# pse84 register map
Vendor: Cypress Semiconductor; Series: PSE84; File version: 1.0
CPU: CM33 r0p1, little endian, MPU, FPU, VTOR, 3 interrupt priority bits
Registers are 32-bit, read-write, reset 0x0 unless marked. A register's access mark holds for its fields unless they carry their own. Offsets are from the block's base; [hi:lo] are bit positions; lines under a group give offsets from that group; {n}, {i} and the like mark numbered series; 'fields as' and 'values as' point back to an identical list; <NAME> marks a mode.

## SRSS (part 3 of 3) — SRSS Core Registers
Base 0x42400000
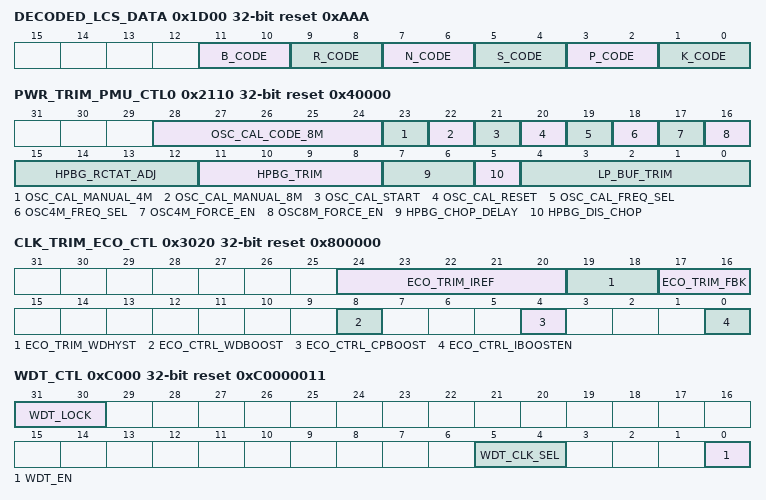
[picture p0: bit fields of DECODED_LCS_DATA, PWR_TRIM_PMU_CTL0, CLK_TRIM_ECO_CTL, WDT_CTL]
0x1D00 DECODED_LCS_DATA ro reset 0xAAA — Decoded Life Cycle Stage Data Register
  [11:10] B_CODE — Indicates status of LCS 'B' bit. 00=Unprogrammed, 11=Valid, 10/01=Invalid
  [9:8] R_CODE — Indicates status of LCS 'R' bit. 00=Unprogrammed, 11=Valid, 10/01=Invalid
  [7:6] N_CODE — Indicates status of LCS 'N' bit*. 00=Unprogrammed, 11=Valid, 10/01=Invalid. Will be '00' if R_CODE is set in RMA LCS
  [5:4] S_CODE — Indicates status of LCS 'S' bit*. 00=Unprogrammed, 11=Valid, 10/01=Invalid. Will be '11' if R_CODE is set in RMA LCS
  [3:2] P_CODE — Indicates status of LCS 'P' bit*. 00=Unprogrammed, 11=Valid, 10/01=Invalid. Will be '11' if R_CODE is set in RMA LCS
  [1:0] K_CODE — Indicates status of LCS 'K' bit. 00=Unprogrammed, 11=Valid, 10/01=Invalid
0x2110 PWR_TRIM_PMU_CTL0 reset 0x40000 — PMU Trim Register 0
  [28:24] OSC_CAL_CODE_8M — Manual trim code to apply to 8MHz oscillator. Only used if osc_cal_manual_8M=1.
  [23] OSC_CAL_MANUAL_4M — Set to use manual cal code for 3.2/4MHz oscillator 0 Use calibration result 1 Use osc_cal_code_4M<4:0>
  [22] OSC_CAL_MANUAL_8M — Set to use manual cal code for 8MHz oscillator 0 Use calibration result 1 Use osc_cal_code_8M<4:0>
  [21] OSC_CAL_START — Start oscillator calibration
  [20] OSC_CAL_RESET — Reset osc cal codes and cal_done signal
  [19] OSC_CAL_FREQ_SEL — Select oscillator to calibrate 0: 8MHz 1: 3.2M/4MHz
  [18] OSC4M_FREQ_SEL — PWM oscillator frequency select 0: 4.0MHz 1 : 3.2MHz
  [17] OSC4M_FORCE_EN — 3.2/4MHz (PWM) oscillator enable - use for Calibration 0: Auto (powerup when used) 1: Enabled (3.2/4MHz always on)
  [16] OSC8M_FORCE_EN — 8MHz oscillator enable - use for Calibration 0: Auto (powerup when used) 1: Enabled (8MHz always on)
  [15:12] HPBG_RCTAT_ADJ — High power bandgap adjust for 0TC (TTTT,50C)
  [11:8] HPBG_TRIM — High power bandgap reference voltage trim Setting VOUT @1.16V VOUT percent 0111 41mV +3.4 percent 0110 35mV +2.9 percent 0101 29mV +2.4 percent 0100 23mV +1.9 percent 0011 18mV +1.5 percent 0010 12mV +1.0 percent 0001 6mV +0.5 percent 0000 0mV 0.0 percent 1111 -5mV -0.4 percent 1110 -11mV -1.0 percent 1101 -16mV -1.4 percent 1100 -22mV -1.9 percent 1011 -27mV -2.4 percent 1010 -32mV -2.8 percent 1001 -38mV -3.4 percent 1000 -43mV -3.9 percent
  [7:6] HPBG_CHOP_DELAY — HPBG chopping delay Setting Delay 00 16us 01 32us 10 64us 11 128us
  [5] HPBG_DIS_CHOP — HPBG disable chop
  [4:0] LP_BUF_TRIM — LP buffer voltage trim, 2's compliment format Setting Vref(V) Setting Vref(V) 00000 0.600 10000 0.520 (-13.3 percent) 00001 0.605 (+0.83 percent) 10001 0.525 (-12.5 percent) 00010 0.610 (+1.67 percent) 10010 0.530 (-11.7 percent) 00011 0.615 (+2.50 percent) 10011 0.535 (-10.8 percent) 00100 0.620 (+3.33 percent) 10100 0.540 (-10.0 percent) 00101 0.625 (+4.17 percent) 10101 0.545 (-9.17 percent) 00110 0.630 (+5.00 percent) 10110 0.550 (-8.33 percent) 00111 0.635 (+5.83 percent) 10111 0.555 (-7.50 percent) 01000 0.640 (+6.67 percent) 11000 0.560 (-6.67 percent) 01001 0.645 (+7.50 percent) 11001 0.565 (-5.83 percent) 01010 0.650 (+8.33 percent) 11010 0.570 (-5.00 percent) 01011 0.655 (+9.17 percent) 11011 0.575 (-4.17 percent) 01100 0.660 (+10.0 percent) 11100 0.580 (-3.33 percent) 01101 0.665 (+10.8 percent) 11101 0.585 (-2.50 percent) 01110 0.670 (+11.7 percent) 11110 0.590 (-1.67 percent) 01111 0.675 (+12.5 percent) 11111 0.595 (-0.83 percent)
0x3020 CLK_TRIM_ECO_CTL reset 0x800000 — ECO Trim Register
  [24:20] ECO_TRIM_IREF — Current bias trim input pin
  [19:18] ECO_TRIM_WDHYST — Watchdog hysteresis trim
  [17:16] ECO_TRIM_FBK — Feedback resistance trim
  [8] ECO_CTRL_WDBOOST — Watchdog trim
  [4] ECO_CTRL_CPBOOST — Amplitude trim
  [0] ECO_CTRL_IBOOSTEN — Current boost enable input pin
0x4000 RAM_TRIM group — SRAM Trim registers
  {0x0+4j} TRIM_RAM_CTL[{j}] (j=0..9) — Trim Register for RAM Type 0
    [31:0] TRIM — Trim value for RAM Type 0
0xC000 WDT_CTL reset 0xC0000011 — Watchdog Counter Control Register (Type A)
  [31:30] WDT_LOCK — Prohibits writing to WDT_*, CLK_ILO_CONFIG, CLK_SELECT.LFCLK_SEL, and CLK_TRIM_ILO_CTL registers when not equal 0. Requires at least two different writes to unlock. A change in WDT_LOCK takes effect beginning with the next write cycle. Note that this field is 2 bits to force multiple writes only. It represents only a single write protect signal protecting all those registers at the same time. WDT will lock on any reset. This field is not retained during DEEPSLEEP or HIBERNATE mode, so the WDT will be locked after wakeup from these modes.
    0=NO_CHG (No effect); 1=CLR0 (Clears bit 0); 2=CLR1 (Clears bit 1); 3=SET01 (Sets both bits 0 and 1)
  [5:4] WDT_CLK_SEL — Select source for WDT. Not all products support all clock sources. Selecting a clock source that is not supported will result in undefined behavior. Writes to this field are ignored unless the WDT is unlock using WDT_LOCK register. It takes four cycles of the originally selected clock to switch away from it. Do not disable the original clock during this time.
    0=ILO (ILO - Internal Low-speed Oscillator, if present. With this option selected, ILO reset is suppressed in Hibernate mode.); 1=PILO (PILO - Precision ILO. If present. With this option selected, PILO reset is suppressed in Hibernate mode.); 2=RTC (RTC - Selected clk_rtc source, if present. This choice is not recommended for applications that rely upon the watchdog timer for safety or security, unless the product supports clock supervision of clk_rtc (CSV_RTC). Generation of clk_rtc is not protected by WDT_LOCK and is in a different memory region with potentially different security attributes.)
  [0] WDT_EN — Enable this watchdog timer. This field is retained during DEEPSLEEP and HIBERNATE modes.
0xC004 WDT_CNT — Watchdog Counter Count Register (Type A)
  [31:0] COUNTER — Current value of WDT Counter. The write feature of this register is for verification purpose, have no synchronization, and can only be applied when the WDT is fully off. When writing, the value is updated immediately in the WDT counter, but it will read back as the old value until this register resynchronizes just after the negedge of selected WDT clock. Writes will be ignored if they occur when the WDT is enabled.
0xC008 WDT_MATCH reset 0x1000 — Watchdog Counter Match Register (Type A)
  [31:0] MATCH — Match value for Watchdog counter. Every time WDT_COUNTER reaches MATCH an interrupt is generated. Two unserviced interrupts will lead to a system reset (i.e. at the third match).
0xC00C WDT_MATCH2 reset 0x1F — Watchdog Counter Match Register 2 (Type A)
  [4:0] IGNORE_BITS_ABOVE — The number of bits to be considered for matching starting from LSb of the register. Bit indices above this setting are NOT checked against MATCH. This value provides control over the time-to-reset of the watchdog (which happens after 3 successive matches). The four LSBs cannot be ignored for matching. Settings <3 behave like a setting of 3. If the setting is higher than the number of bits in the WDT counter, all actual bits in the counter are matched.
{0xC100+0x80*i} WDT[{i}] (i=0..3) group — Watchdog Timer (Type B)
  0x00 CTL reset 0x80000001 — WDT Control Register
    [31] ENABLE — Enable watchdog. May take up to three clk_ilo0 cycles to take effect. When ENABLE changes from 1->0, the counter is cleared. Do not enter DEEPSLEEP or HIBERNATE mode if ENABLE<>ENABLED. This can be done by waiting until ENABLE==ENABLED whenever ENABLE is changed. 0: Counter is disabled (not clocked). 1: Counter is enabled (counting up)
    [0] ENABLED ro — Indicates actual state of watchdog. May lag ENABLE by up to three clk_ilo0 cycles.
  0x04 LOWER_LIMIT — WDT Lower Limit Register
    [31:0] LOWER_LIMIT — Lower limit for watchdog. See LOWER_ACTION.
  0x08 UPPER_LIMIT reset 0x8000 — WDT Upper Limit Register
    [31:0] UPPER_LIMIT — Upper limit for watchdog. See UPPER_ACTION.
  0x0C WARN_LIMIT — WDT Warn Limit Register
    [31:0] WARN_LIMIT — Warn limit for watchdog. See WARN_ACTION.
  0x10 CONFIG reset 0x10 — WDT Configuration Register
    [31] DEBUG_RUN — Pauses/runs this counter while a debugger is connected. Other behaviors are unchanged during debugging, including service, configuration updates and enable/disable. Note it may take up to two clk_ilo0 cycles for the counter to pause and another two cycles to unpause, due to internal synchronization. If the debugger is connected for at least two clk_ilo0 cycles, the LOWER_ACTION is ignored until after the first service after the debugger is disconnected. This prevents an unintentional trigger of the LOWER_ACTION before the firmware realigns the servicing period. After the first service, LOWER_ACTION behaves as configured. If the debugger is disconnected before two clk_ilo0 cycles, the LOWER_ACTION may or may not be ignored. 0: When debugger connected, counter pauses incrementing as configured in DEBUG_TRIGGER_EN. 1: When debugger connected, counter increments normally, but reset generation is blocked.
    [30] HIB_PAUSE — Pauses/runs this counter when the system is in HIBERNATE. Note it may take up to two clk_ilo0 cycles for the counter to pause, due to internal synchronization. After wakeup, the LOWER_ACTION is ignored until after the first service. This prevents an unintentional trigger of the LOWER_ACTION before the firmware realigns the servicing period. After the first service, LOWER_ACTION behaves as configured. 0: Counter behaves normally during HIBERNATE. 1: Counter pauses during HIBERNATE.
    [29] DPSLP_PAUSE — Pauses/runs this counter when the system is in DEEPSLEEP. Note it may take up to two clk_ilo0 cycles for the counter to pause, due to internal synchronization. During DEEPSLEEP wakeup, the pause request is removed when clk_hf0 starts clocking, and then it may take up to two clk_ilo0 cycles for the counter to start. After wakeup, the LOWER_ACTION is ignored until after the first service. This prevents an unintentional trigger of the LOWER_ACTION before the firmware realigns the servicing period. After the first service, LOWER_ACTION behaves as configured. 0: Counter behaves normally during DEEPSLEEP. 1: Counter pauses during DEEPSLEEP.
    [28] DEBUG_TRIGGER_EN — Enables the trigger input for WDT to pause the counter during debug mode. To pause at a breakpoint while debugging, configure the trigger matrix to connect the related CPU halted signal to the trigger input for this WDT, and then set this bit. It takes up to two clk_ilo0 cycles for the trigger signal to be processed. Triggers that are less than two clk_ilo0 cycles may be missed. Synchronization error can accumulate each time it is halted. 0: Pauses the counter whenever a debug probe is connected. 1: Pauses the counter whenever a debug probe is connected and the trigger input is high.
    [12] AUTO_SERVICE — Automatically service when the count value reaches WARN_LIMIT. This allows creation of a periodic interrupt if this counter is not needed as a watchdog. This field is ignored when LOWER_ACTION<>NOTHING or when UPPER_ACTION<>NOTHING.
    [8] WARN_ACTION — Action taken when the count value reaches WARN_LIMIT. The minimum setting to achieve a periodic interrupt is WARN_LIMIT==1. A setting of zero will trigger once but not periodically. For WARN_LIMIT >= 2: The action is triggered on same edge when it meets this condition. For WARN_LIMIT < 2 : The action may take up to one extra clk_ilo0 cycle to trigger.
      0=NOTHING (Do nothing); 1=INT (Trigger an interrupt.)
    [4] UPPER_ACTION — Action taken if this watchdog is not serviced before UPPER_LIMIT is reached. The counter stops counting when UPPER_LIMIT is reached, regardless of UPPER_ACTION setting. UPPER_ACTION is ignored (i.e. treated as NOTHING) when a debugger is connected. For UPPER_LIMIT >= 2: The action is triggered on same edge when it meets this condition. For UPPER_LIMIT < 2: The action may take up to one extra clk_ilo0 cycle to trigger.
      0=NOTHING (Do nothing); 1=RESET (Trigger a reset.)
    [0] LOWER_ACTION — Action taken if this watchdog is serviced before LOWER_LIMIT is reached. LOWER_ACTION is ignored (i.e. treated as NOTHING) when a debugger is connected and/or when the chip is in DEEPSLEEP/HIBERNATE modes. For LOWER_LIMIT >= 1: The action is triggered on same edge when it meets this condition. For LOWER_LIMIT == 0: No action is triggered.
      0=NOTHING (Do nothing); 1=RESET (Trigger a reset.)
  0x14 CNT — WDT Count Register
    [31:0] CNT — Current value of subcounter for this WDT. This field may lag the actual count value by up to one clk_ilo0 cycle, due to internal synchronization. When this subcounter is disabled and unlocked, the count value can be written for verification and debugging purposes. Software writes are always ignored when the subcounter is enabled.
  0x40 LOCK reset 0x3 — WDT Lock register
    [1:0] WDT_LOCK — Prohibits writing control and configuration registers related to this WDT when not equal 0 (as specified in the other register descriptions). Requires at least two different writes to unlock. Note that this field is 2 bits to force multiple writes only. This register also locks the clk_ilo0 settings.
      values as WDT_CTL.WDT_LOCK
  0x44 SERVICE — WDT Service register
    [0] SERVICE — Services the watchdog. This resets the count value to zero. This may take up to three clk_ilo0 cycle to take effect. Hardware clears this bit, after necessary synchronization. To ensure a pending SERVICE write is reflected, firmware should wait until this bit reads low before attempting to write SERVICE=1. If WDT is disabled, SERVICE will not trigger a LOWER_ACTION and will not clear a preloaded count value.
  0x50 INTR — WDT Interrupt Register
    [0] WDT — WDT Interrupt Request. This bit is set as configured by WDT action and limits. Due to internal synchronization, it takes up to 8 SYSCLK cycles to update after a W1C or reading this register and during this time AHB bus is stalled.
  0x54 INTR_SET — WDT Interrupt Set Register
    [0] WDT — Set interrupt. Due to internal synchronization, it takes up to 8 SYSCLK cycles to update after a W1S or reading from this register and during this time AHB bus is stalled.
  0x58 INTR_MASK — WDT Interrupt Mask Register
    [0] WDT — Mask for watchdog timer. Clearing this bit will not forward the interrupt to the CPU.
  0x5C INTR_MASKED ro — WDT Interrupt Masked Register
    [0] WDT — Logical and of corresponding request and mask bits. Due to internal synchronization, it takes up to 8 SYSCLK cycles to read from this register. During this time AHB bus is stalled.
{0xD000+0x40*i} MCWDT_STRUCT[{i}] (i=0..1) group — Multi-Counter Watchdog Timer (Type A)
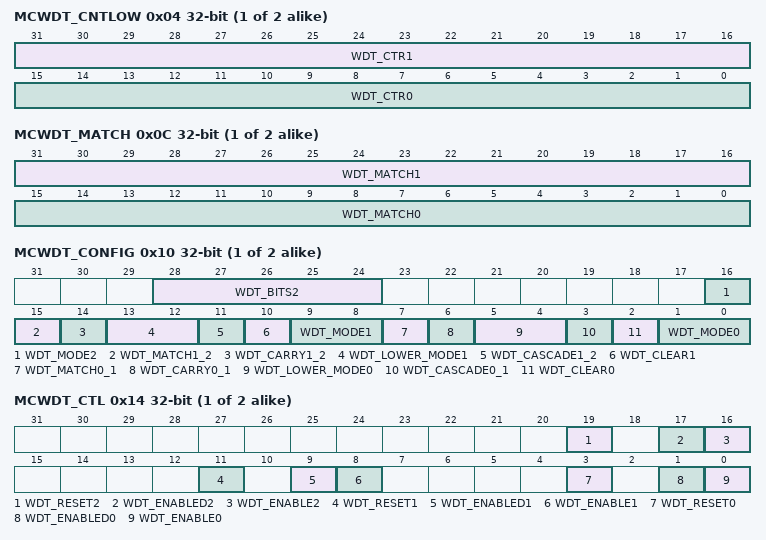
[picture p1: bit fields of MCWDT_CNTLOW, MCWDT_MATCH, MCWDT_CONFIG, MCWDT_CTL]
  0x04 MCWDT_CNTLOW — Multi-Counter Watchdog Sub-counters 0/1
    [31:16] WDT_CTR1 — Current value of sub-counter 1 for this MCWDT. Software writes are ignored when the sub-counter is enabled
    [15:0] WDT_CTR0 — Current value of sub-counter 0 for this MCWDT. Software writes are ignored when the sub-counter is enabled.
  0x08 MCWDT_CNTHIGH — Multi-Counter Watchdog Sub-counter 2
    [31:0] WDT_CTR2 — Current value of sub-counter 2 for this MCWDT. Software writes are ignored when the sub-counter is enabled
  0x0C MCWDT_MATCH — Multi-Counter Watchdog Counter Match Register
    [31:16] WDT_MATCH1 — Match value for sub-counter 1 of this MCWDT
    [15:0] WDT_MATCH0 — Match value for sub-counter 0 of this MCWDT
  0x10 MCWDT_CONFIG — Multi-Counter Watchdog Counter Configuration
    [28:24] WDT_BITS2 — Bit to observe for WDT_INT2: 0: Assert after bit0 of WDT_CTR2 toggles (one int every tick) ... 31: Assert after bit31 of WDT_CTR2 toggles (one int every 2^31 ticks)
    [16] WDT_MODE2 — Watchdog Counter 2 Mode.
      0=NOTHING (Free running counter with no interrupt requests); 1=INT (Free running counter with interrupt request that occurs one LFCLK cycle after the specified bit in CTR2 toggles (see WDT_BITS2).)
    [15] WDT_MATCH1_2 — Specifies matching behavior when WDT_CASCADE1_2==1. When WDT_CASCADE1_2==0, this bit is not used and match is based on counter 2 alone. 0: Match based on counter 2 alone. 1: Match based on counter 2 and counter 1 matching simultaneously.
    [14] WDT_CARRY1_2 — Carry out behavior that applies when WDT_CASCADE1_2==1. This bit is not used when WDT_CASCADE1_2==0. 0: carry out on counter 1 match. 1: carry out on counter 1 roll-over.
    [13:12] WDT_LOWER_MODE1 — Watchdog Counter Action on service before lower limit.
      0=NOTHING (Do nothing); 1=INT (Assert WDT_INTx); 2=RESET (Assert WDT Reset)
    [11] WDT_CASCADE1_2 — Cascade Watchdog Counters 1,2. Counter 2 increments the cycle after WDT_CTR1=WDT_MATCH1. It is allowed to cascade all three WDT counters. 0: Independent counters 1: Cascaded counters. When cascading all three counters, WDT_CLEAR1 must be 1.
    [10] WDT_CLEAR1 — Clear Watchdog Counter when WDT_CTR1==WDT_MATCH1. In other words WDT_CTR1 divides LFCLK by (WDT_MATCH1+1). 0: Free running counter 1: Clear on match. In this mode, the minimum legal setting of WDT_MATCH1 is 1.
    [9:8] WDT_MODE1 — Watchdog Counter Action on Match. Action is taken on the next increment after the values match (WDT_CTR1=WDT_MATCH1).
      0=NOTHING (Do nothing); 1=INT (Assert WDT_INTx); 2=RESET (Assert WDT Reset); 3=INT_THEN_RESET (Assert WDT_INTx, assert WDT Reset after 3rd unhandled interrupt)
    [7] WDT_MATCH0_1 — Specifies matching behavior when WDT_CASCADE0_1==1. When WDT_CASCADE0_1==0, this bit is not used and match is based on counter 1 alone. 0: Match based on counter 1 alone. 1: Match based on counter 1 and counter 0 matching simultaneously.
    [6] WDT_CARRY0_1 — Carry out behavior that applies when WDT_CASCADE0_1==1. This bit is not used when WDT_CASCADE0_1==0. 0: carry out on counter 0 match. 1: carry out on counter 0 roll-over.
    [5:4] WDT_LOWER_MODE0 — Watchdog Counter Action on service before lower limit.
      values as WDT_LOWER_MODE1
    [3] WDT_CASCADE0_1 — Cascade Watchdog Counters 0,1. Counter 1 increments the cycle after WDT_CTR0=WDT_MATCH0. 0: Independent counters 1: Cascaded counters
    [2] WDT_CLEAR0 — Clear Watchdog Counter when WDT_CTR0=WDT_MATCH0. In other words WDT_CTR0 divides LFCLK by (WDT_MATCH0+1). 0: Free running counter 1: Clear on match. In this mode, the minimum legal setting of WDT_MATCH0 is 1.
    [1:0] WDT_MODE0 — Watchdog Counter Action on Match. Action is taken on the next increment after the values match (WDT_CTR0=WDT_MATCH0).
      values as WDT_MODE1
  0x14 MCWDT_CTL — Multi-Counter Watchdog Counter Control
    [19] WDT_RESET2 — Resets counter 2 back to 0000. Hardware will reset this bit after counter was reset. This will take up to one LFCLK cycle to take effect.
    [17] WDT_ENABLED2 ro — Indicates actual state of counter. May lag WDT_ENABLE2 by up to two LFCLK cycles.
    [16] WDT_ENABLE2 — Enable subcounter 2. May take up to 2 LFCLK cycles to take effect. 0: Counter is disabled (not clocked) 1: Counter is enabled (counting up)
    [11] WDT_RESET1 — Resets counter 1 back to 0000. Hardware will reset this bit after counter was reset. This will take up to one LFCLK cycle to take effect.
    [9] WDT_ENABLED1 ro — Indicates actual state of counter. May lag WDT_ENABLE1 by up to two LFCLK cycles.
    [8] WDT_ENABLE1 — Enable subcounter 1. May take up to 2 LFCLK cycles to take effect. 0: Counter is disabled (not clocked) 1: Counter is enabled (counting up)
    [3] WDT_RESET0 — Resets counter 0 back to 0000. Hardware will reset this bit after counter was reset. This will take up to one LFCLK cycle to take effect.
    [1] WDT_ENABLED0 ro — Indicates actual state of counter. May lag WDT_ENABLE0 by up to two LFCLK cycles.
    [0] WDT_ENABLE0 — Enable subcounter 0. May take up to 2 LFCLK cycles to take effect. 0: Counter is disabled (not clocked) 1: Counter is enabled (counting up)
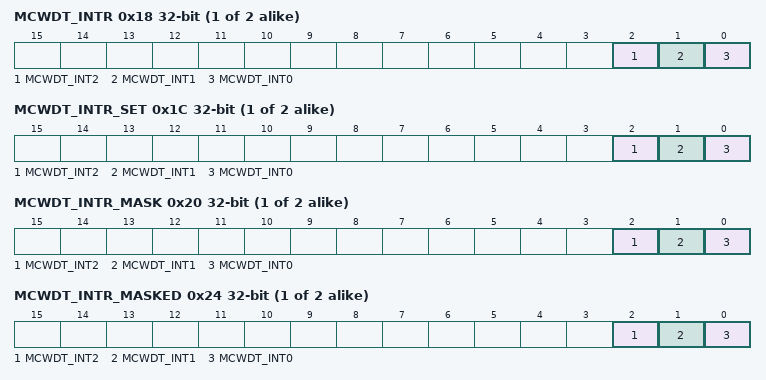
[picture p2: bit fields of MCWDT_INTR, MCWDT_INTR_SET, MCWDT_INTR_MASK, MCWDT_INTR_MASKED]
  0x18 MCWDT_INTR — Multi-Counter Watchdog Counter Interrupt Register
    [2] MCWDT_INT2 — MCWDT Interrupt Request for sub-counter 2. This bit is set by hardware as configured by this registers. This bit must be cleared by firmware. Clearing this bit also prevents Reset from happening when WDT_MODE2=3.
    [1] MCWDT_INT1 — MCWDT Interrupt Request for sub-counter 1. This bit is set by hardware as configured by this registers. This bit must be cleared by firmware. Clearing this bit also prevents Reset from happening when WDT_MODE1=3.
    [0] MCWDT_INT0 — MCWDT Interrupt Request for sub-counter 0. This bit is set by hardware as configured by this registers. This bit must be cleared by firmware. Clearing this bit also prevents Reset from happening when WDT_MODE0=3.
  0x1C MCWDT_INTR_SET — Multi-Counter Watchdog Counter Interrupt Set Register
    [2] MCWDT_INT2 — Set interrupt for MCWDT_INT2
    [1] MCWDT_INT1 — Set interrupt for MCWDT_INT1
    [0] MCWDT_INT0 — Set interrupt for MCWDT_INT0
  0x20 MCWDT_INTR_MASK — Multi-Counter Watchdog Counter Interrupt Mask Register
    [2] MCWDT_INT2 — Mask for sub-counter 2. This controls if the interrupt is forwarded to the CPU. 0: Interrupt is masked (not forwarded). 1: Interrupt is forwarded.
    [1] MCWDT_INT1 — Mask for sub-counter 1. This controls if the interrupt is forwarded to the CPU. 0: Interrupt is masked (not forwarded). 1: Interrupt is forwarded.
    [0] MCWDT_INT0 — Mask for sub-counter 0. This controls if the interrupt is forwarded to the CPU. 0: Interrupt is masked (not forwarded). 1: Interrupt is forwarded.
  0x24 MCWDT_INTR_MASKED ro — Multi-Counter Watchdog Counter Interrupt Masked Register
    [2] MCWDT_INT2 — Logical and of corresponding request and mask bits.
    [1] MCWDT_INT1 — Logical and of corresponding request and mask bits.
    [0] MCWDT_INT0 — Logical and of corresponding request and mask bits.
  0x28 MCWDT_LOCK — Multi-Counter Watchdog Counter Lock Register
    [31:30] MCWDT_LOCK — Prohibits writing control and configuration registers related to this MCWDT when not equal 0 (as specified in the other register descriptions). Requires at least two different writes to unlock. Note that this field is 2 bits to force multiple writes only. Each MCWDT has a separate local lock. LFCLK settings are locked by the global WDT_LOCK register, and this register has no effect on that.
      values as WDT_CTL.WDT_LOCK
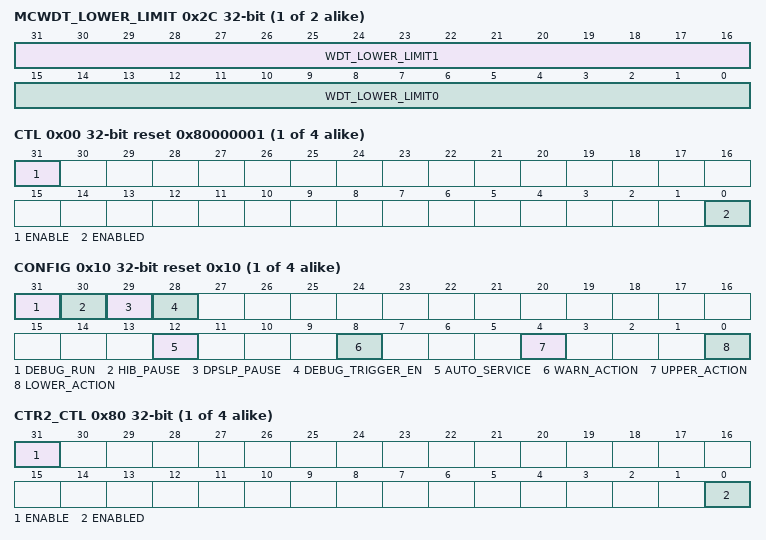
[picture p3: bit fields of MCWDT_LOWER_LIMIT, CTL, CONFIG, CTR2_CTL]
  0x2C MCWDT_LOWER_LIMIT — Multi-Counter Watchdog Counter Lower Limit Register
    [31:16] WDT_LOWER_LIMIT1 — Lower limit for sub-counter 1 of this MCWDT
    [15:0] WDT_LOWER_LIMIT0 — Lower limit for sub-counter 0 of this MCWDT
{0xE000+0x100*i} MCWDT[{i}] (i=0..3) group — Multi-Counter Watchdog Timer (Type B)
  {0x0+0x20*j} CTR[{j}] (j=0..1) group — MCWDT Configuration for Subcounter 0 and 1
    0x00 CTL — MCWDT Subcounter Control Register
      [31] ENABLE — Enable subcounter. May take up to 2 clk_lf cycles to take effect. When ENABLE changes from 1->0, the counter is cleared. 0: Counter is disabled (not clocked) 1: Counter is enabled (counting up)
      [0] ENABLED ro — Indicates actual state of this subcounter. May lag ENABLE by up to two clk_lf cycles.
    0x04 LOWER_LIMIT — MCWDT Subcounter Lower Limit Register
      [15:0] LOWER_LIMIT — Lower limit for this MCWDT subcounter. See LOWER_ACTION.
    0x08 UPPER_LIMIT — MCWDT Subcounter Upper Limit Register
      [15:0] UPPER_LIMIT — Upper limit for this MCWDT subcounter. See UPPER_ACTION.
    0x0C WARN_LIMIT — MCWDT Subcounter Warn Limit Register
      [15:0] WARN_LIMIT — Warn limit for this MCWDT subcounter. See WARN_ACTION.
    0x10 CONFIG — MCWDT Subcounter Configuration Register
      [31] DEBUG_RUN — Pauses/runs this counter while a debugger is connected. Other behaviors are unchanged during debugging, including service, configuration updates and enable/disable. Note it may take up to two clk_lf cycles for the counter to pause, due to internal synchronization. When (DEBUG_RUN==1 or DEBUG_TRIGGER_EN==0) and the debugger is connected for at least two clk_lf cycles, the LOWER_ACTION is ignored until after the first service after the debugger is disconnected. After the debugger is disconnected, the LOWER_ACTION is ignored until after the first service. This prevents an unintentional trigger of the LOWER_ACTION before the firmware realigns the servicing period. After the first service, LOWER_ACTION behaves as configured. If the debugger is disconnected before two clk_lf cycles, the LOWER_ACTION may or may not be ignored. 0: When debugger connected, counter pauses incrementing as configured in DEBUG_TRIGGER_EN. 1: When debugger connected, counter increments normally, but reset generation is blocked. To block LOWER_ACTION generation, write DEBUG_TRIGGER_EN==0.
      [30] SLEEPDEEP_PAUSE — Pauses/runs this counter when the corresponding processor is in SLEEPDEEP. Note it may take up to two clk_lf cycles for the counter to pause and up to two clk_lf cycles for it to unpause, due to internal synchronization. After wakeup, the LOWER_ACTION is ignored until after the first service. This prevents an unintentional trigger of the LOWER_ACTION before the firmware realigns the servicing period. After the first service, LOWER_ACTION behaves as configured. 0: Counter runs normally regardless of processor mode. 1: Counter pauses when corresponding processor is in SLEEPDEEP.
      [28] DEBUG_TRIGGER_EN — Enables the trigger input for this MCWDT to pause the counter during debug mode. To pause at a breakpoint while debugging, configure the trigger matrix to connect the related CPU halted signal to the trigger input for this MCWDT, and then set this bit. It takes up to two clk_lf cycles for the trigger signal to be processed. Triggers that are less than two clk_lf cycles may be missed. Synchronization errors can accumulate each time it is halted. 0: Pauses the counter whenever a debug probe is connected. 1: Pauses the counter whenever a debug probe is connected and the trigger input is high.
      [12] AUTO_SERVICE — Automatically service when the count value reaches WARN_LIMIT. This allows creation of a periodic interrupt if this counter is not needed as a watchdog. This field is ignored when LOWER_ACTION<>NOTHING or when UPPER_ACTION<>NOTHING.
      [8] WARN_ACTION — Action taken when the count value reaches WARN_LIMIT. The minimum setting to achieve a periodic interrupt is WARN_LIMIT==1. A setting of zero will trigger once but not periodically. For WARN_LIMIT >= 2: The action is triggered on same edge when it meets this condition. For WARN_LIMIT == [0,1] : The action may take up to one extra clk_lf cycle to trigger.
        0=NOTHING (Do nothing); 1=INT (Trigger an interrupt.)
      [5:4] UPPER_ACTION — Action taken if this watchdog is not serviced before UPPER_LIMIT is reached. The counter stops counting when UPPER_LIMIT is reached, regardless of UPPER_ACTION setting. UPPER_ACTION is ignored (i.e. treated as NOTHING) when a debugger is connected.
        0=NOTHING (Do nothing); 1=FAULT (N/A); 2=FAULT_THEN_RESET (Trigger a fault. Further, trigger a system-wide reset if the fault is not serviced and the watchdog is not cleared within 6 clk_lf cycles. It can take up to 3 clk_lf cycles for the fault to be transferred to the fault manager, which gives at least 3 clk_lf cycles for software to respond. For UPPER_LIMIT >= 2: The action is triggered on same edge when it meets this condition. For UPPER_LIMIT < 2: The action may take up to one extra clk_lf cycle to trigger.)
      [1:0] LOWER_ACTION — Action taken if this watchdog is serviced before LOWER_LIMIT is reached. LOWER_ACTION is ignored (i.e. treated as NOTHING) when a debugger is connected and/or when the corresponding processor is in SLEEPDEEP.
        0=NOTHING (Do nothing); 1=FAULT (N/A); 2=FAULT_THEN_RESET (Trigger a fault. Further, trigger a system-wide reset if the fault is not serviced and the watchdog is not cleared within 6 clk_lf cycles. It can take up to 3 clk_lf cycles for the fault to be transferred to the fault manager, which gives at least 3 clk_lf cycles for software to respond. For LOWER_LIMIT >= 1: The action is triggered on same edge when it meets this condition. For LOWER_LIMIT == 0: No action is triggered.)
    0x14 CNT — MCWDT Subcounter Count Register
      [15:0] CNT — Current value of subcounter for this MCWDT. This field may lag the actual count value by up to one clk_lf cycle, due to internal synchronization. When this subcounter is disabled and unlocked, the count value can be written for verification and debugging purposes. Software writes are always ignored when the subcounter is enabled.
  0x40 CPU_SELECT — MCWDT CPU selection register
    [1:0] CPU_SEL — Assigns this MCWDT to a CPU. This selects which CPU SLEEPDEEP signal is used for SLEEPDEEP_PAUSE.
  0x80 CTR2_CTL — MCWDT Subcounter 2 Control register
    fields as MCWDT[0].CTR[0].CTL
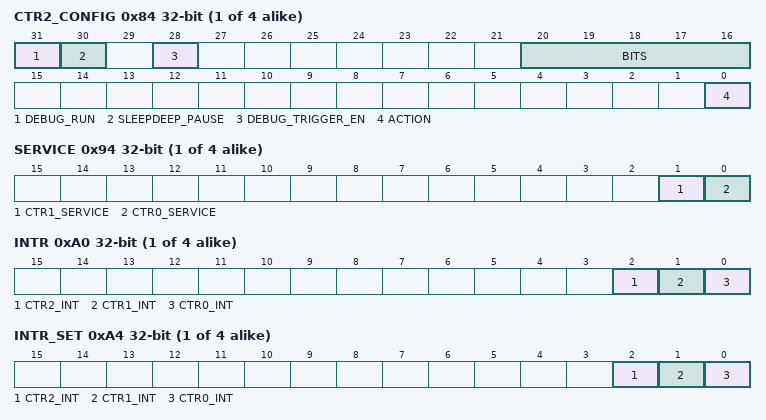
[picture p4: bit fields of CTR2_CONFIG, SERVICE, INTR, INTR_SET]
  0x84 CTR2_CONFIG — MCWDT Subcounter 2 Configuration register
    [31] DEBUG_RUN — Pauses/runs this counter while a debugger is connected. Other behaviors are unchanged during debugging, including service, configuration updates and enable/disable. Note it may take up to two clk_lf cycles for the counter to pause and another two cycles to unpause, due to internal synchronization. 0: When debugger connected, counter pauses incrementing as configured in DEBUG_TRIGGER_EN. 1: When debugger connected, counter increments normally, but reset generation is blocked.
    [30] SLEEPDEEP_PAUSE — Pauses/runs this counter when the corresponding processor is in SLEEPDEEP. Note it may take up to two clk_lf cycles for the counter to pause and up to two clk_lf cycles for it to unpause, due to internal synchronization. 0: Counter runs normally regardless of processor mode. 1: Counter pauses when corresponding processor is in SLEEPDEEP.
    [28] DEBUG_TRIGGER_EN — Enables the trigger input for this MCWDT to pause the counter during debug mode. To pause at a breakpoint while debugging, configure the trigger matrix to connect the related CPU halted signal to the trigger input for this MCWDT, and then set this bit. It takes up to two clk_lf cycles for the trigger signal to be processed. Triggers that are less than two clk_lf cycles may be missed. Synchronization errors can accumulate each time it is halted. 0: Pauses the counter whenever a debug probe is connected. 1: Pauses the counter whenever a debug probe is connected and the trigger input is high.
    [20:16] BITS — Bit to observe for a toggle: 0: Do ACTION after CNT[0] toggles (i.e. every tick) . 31: Do ACTION after CNT[31] toggles (i.e. every 2^31 ticks)
    [0] ACTION — Action taken when the specified BIT toggles. Action will be triggered on the same edge where BITS to observe toggle.
      0=NOTHING (Do nothing); 1=INT (Trigger an interrupt)
  0x88 CTR2_CNT — MCWDT Subcounter 2 Count Register
    [31:0] CNT2 — Current value of subcounter 2 for this MCWDT. This field may lag the actual count value by up to one clk_lf cycle, due to internal synchronization. When this subcounter is disabled and unlocked, the count value can be written for verification and debugging purposes. Software writes are always ignored when the subcounter is enabled.
  0x90 LOCK — MCWDT Lock Register
    [1:0] MCWDT_LOCK — Prohibits writing control and configuration registers related to this MCWDT when not equal 0 (as specified in the other register descriptions). Requires at least two different writes to unlock. Note that this field is 2 bits to force multiple writes only. Each MCWDT has a separate local lock.
      values as WDT_CTL.WDT_LOCK
  0x94 SERVICE — MCWDT Service Register
    [1] CTR1_SERVICE — Services subcounter 1. This resets the count value for subcounter 1 to zero. This may take up to three clk_lf cycles to take effect. Hardware clears this bit, after necessary synchronization. To ensure a pending CTR1_SERVICE write is reflected, firmware should wait until this bit reads low before attempting to write CTR1_SERVICE=1. If subcounter 1 is disabled, CTR1_SERVICE will not trigger a LOWER_ACTION and will not clear a preloaded count value.
    [0] CTR0_SERVICE — Services subcounter 0. This resets the count value for subcounter 0 to zero. This may take up to three clk_lf cycles to take effect. Hardware clears this bit, after necessary synchronization. To ensure a pending CTR0_SERVICE write is reflected, firmware should wait until this bit reads low before attempting to write CTR0_SERVICE=1. If subcounter 0 is disabled, CTR0_SERVICE will not trigger a LOWER_ACTION and will not clear a preloaded count value.
  0xA0 INTR — MCWDT Interrupt Register
    [2] CTR2_INT — MCWDT Interrupt Request for sub-counter 2. This bit is set by hardware as configured by this registers. This bit must be cleared by firmware.
    [1] CTR1_INT — MCWDT Interrupt Request for sub-counter 1. This bit is set by hardware as configured by this registers. This bit must be cleared by firmware.
    [0] CTR0_INT — MCWDT Interrupt Request for sub-counter 0. This bit is set by hardware as configured by this registers. This bit must be cleared by firmware.
  0xA4 INTR_SET — MCWDT Interrupt Set Register
    [2] CTR2_INT — Set interrupt for MCWDT_INT2
    [1] CTR1_INT — Set interrupt for MCWDT_INT1
    [0] CTR0_INT — Set interrupt for MCWDT_INT0
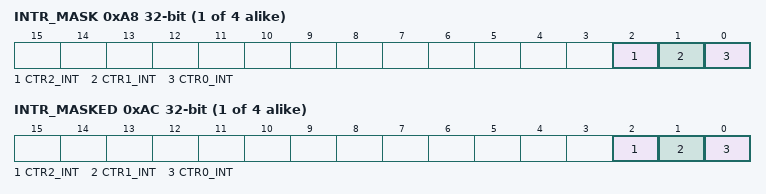
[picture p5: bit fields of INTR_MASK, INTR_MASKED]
  0xA8 INTR_MASK — MCWDT Interrupt Mask Register
    [2] CTR2_INT — Mask for sub-counter 2 for warning interrupt. This controls if the interrupt is forwarded to the CPU. 0: Interrupt is masked (not forwarded). 1: Interrupt is forwarded.
    [1] CTR1_INT — Mask for sub-counter 1 for warning interrupt. This controls if the interrupt is forwarded to the CPU. 0: Interrupt is masked (not forwarded). 1: Interrupt is forwarded.
    [0] CTR0_INT — Mask for sub-counter 0 for warning interrupt. This controls if the interrupt is forwarded to the CPU. 0: Interrupt is masked (not forwarded). 1: Interrupt is forwarded.
  0xAC INTR_MASKED ro — MCWDT Interrupt Masked Register
    [2] CTR2_INT — Logical and of corresponding request and mask bits.
    [1] CTR1_INT — Logical and of corresponding request and mask bits.
    [0] CTR0_INT — Logical and of corresponding request and mask bits.
